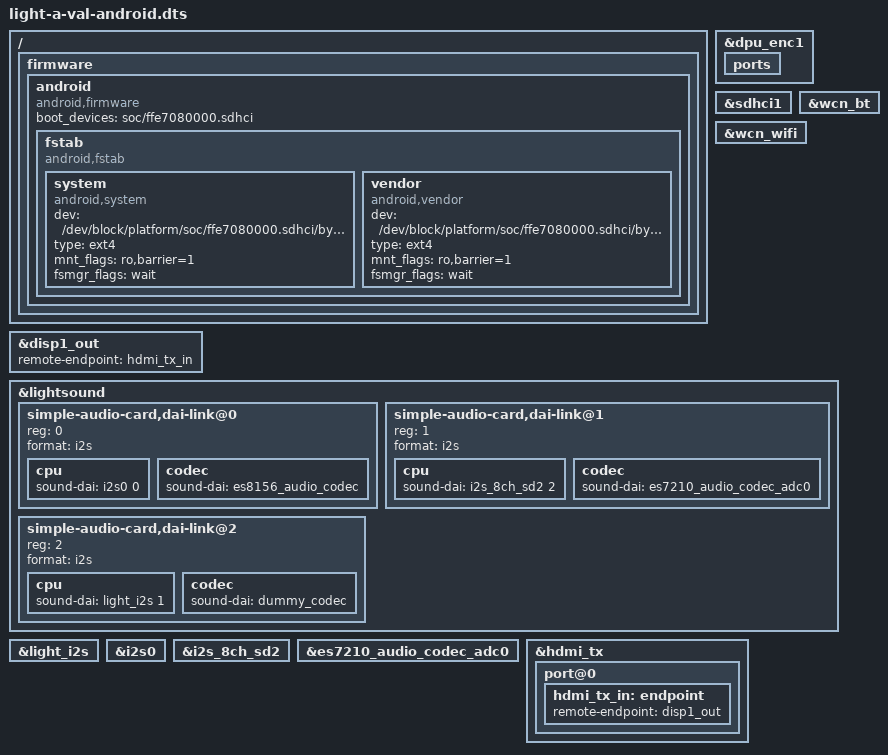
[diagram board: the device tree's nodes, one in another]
/* SPDX-License-Identifier: GPL-2.0 */
/*
 * Copyright (C) 2021 Alibaba Group Holding Limited.
 */

/dts-v1/;

#include "light-a-val-dsi0.dts"

&dpu_enc1 {
        ports {
                /delete-node/ port@0;
        };
};

&disp1_out {
	remote-endpoint = <&hdmi_tx_in>;
};
&sdhci1 {
	status = "okay";
};

&wcn_bt {
	status = "okay";
};

&wcn_wifi {
	status = "okay";
};

&lightsound {
	status = "okay";

        simple-audio-card,dai-link@0 {          /* I2S - AUDIO SYS CODEC 8156*/
                reg = <0>;
                format = "i2s";
                cpu {
                        sound-dai = <&i2s0 0>;
                };
                codec {
                        sound-dai = <&es8156_audio_codec>;
                };
        };

        simple-audio-card,dai-link@1 {          /* I2S - AUDIO SYS CODEC 7210*/
                reg = <1>;
                format = "i2s";
                cpu {
                        sound-dai = <&i2s_8ch_sd2 2>;
                };
                codec {
                        sound-dai = <&es7210_audio_codec_adc0>;
                };
        };

	simple-audio-card,dai-link@2 {          /* I2S - HDMI */
		reg = <2>;
		format = "i2s";
		cpu {
			sound-dai = <&light_i2s 1>;
		};
		codec {
			sound-dai = <&dummy_codec>;
		};
	};
};

&light_i2s {
	status = "okay";
};

&i2s0 {
        status = "okay";
};

&i2s_8ch_sd2 {
        status = "okay";
};

&es7210_audio_codec_adc0 {
        status = "okay";
};

&hdmi_tx {
	status = "okay";

	port@0 {
		/* input */
		hdmi_tx_in: endpoint {
			remote-endpoint = <&disp1_out>;
		};
	};
};

/ {
       firmware {
               android {
                       compatible = "android,firmware";
                       boot_devices = "soc/ffe7080000.sdhci";
                       fstab {
                               compatible = "android,fstab";
                               system {
                                       compatible = "android,system";
                                       dev = "/dev/block/platform/soc/ffe7080000.sdhci/by-name/system";
                                       type = "ext4";
                                       mnt_flags = "ro,barrier=1";
                                       fsmgr_flags = "wait";
                               };
                               vendor {
                                       compatible = "android,vendor";
                                       dev = "/dev/block/platform/soc/ffe7080000.sdhci/by-name/vendor";
                                       type = "ext4";
                                       mnt_flags = "ro,barrier=1";
                                       fsmgr_flags = "wait";
                               };
                       };
               };
       };
};

